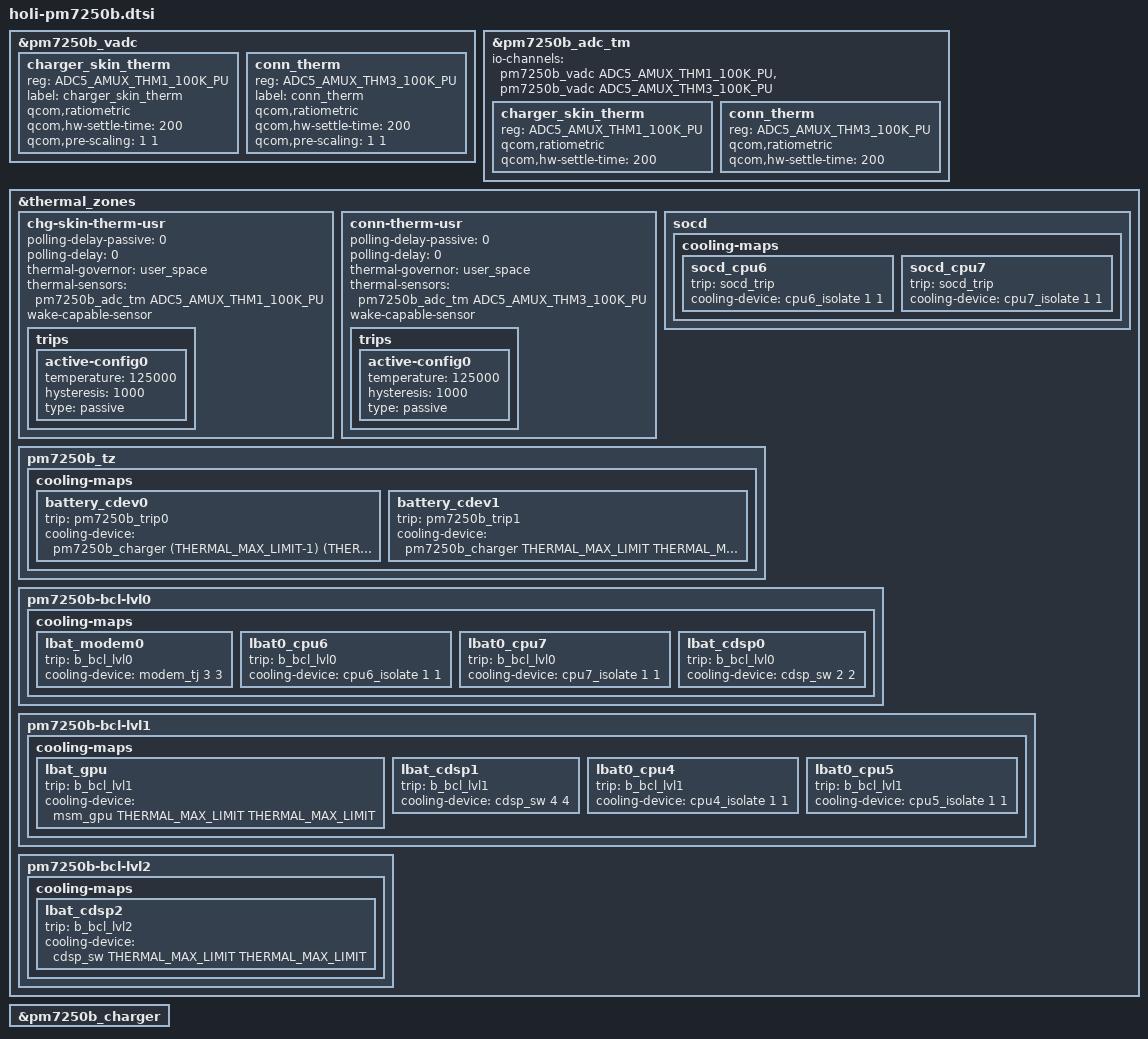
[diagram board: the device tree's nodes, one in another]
#include <dt-bindings/thermal/thermal_qti.h>
#include "pm7250b.dtsi"

&pm7250b_vadc {
	charger_skin_therm {
		reg = <ADC5_AMUX_THM1_100K_PU>;
		label = "charger_skin_therm";
		qcom,ratiometric;
		qcom,hw-settle-time = <200>;
		qcom,pre-scaling = <1 1>;
	};

	conn_therm {
		reg = <ADC5_AMUX_THM3_100K_PU>;
		label = "conn_therm";
		qcom,ratiometric;
		qcom,hw-settle-time = <200>;
		qcom,pre-scaling = <1 1>;
	};
};

&pm7250b_adc_tm {
	io-channels = <&pm7250b_vadc ADC5_AMUX_THM1_100K_PU>,
			<&pm7250b_vadc ADC5_AMUX_THM3_100K_PU>;

	/* Channel nodes */
	charger_skin_therm {
		reg = <ADC5_AMUX_THM1_100K_PU>;
		qcom,ratiometric;
		qcom,hw-settle-time = <200>;
	};

	conn_therm {
		reg = <ADC5_AMUX_THM3_100K_PU>;
		qcom,ratiometric;
		qcom,hw-settle-time = <200>;
	};
};

&thermal_zones {
	chg-skin-therm-usr {
		polling-delay-passive = <0>;
		polling-delay = <0>;
		thermal-governor = "user_space";
		thermal-sensors = <&pm7250b_adc_tm ADC5_AMUX_THM1_100K_PU>;
		wake-capable-sensor;
		trips {
			active-config0 {
				temperature = <125000>;
				hysteresis = <1000>;
				type = "passive";
			};
		};
	};

	conn-therm-usr {
		polling-delay-passive = <0>;
		polling-delay = <0>;
		thermal-governor = "user_space";
		thermal-sensors = <&pm7250b_adc_tm ADC5_AMUX_THM3_100K_PU>;
		wake-capable-sensor;
		trips {
			active-config0 {
				temperature = <125000>;
				hysteresis = <1000>;
				type = "passive";
			};
		};
	};
};

&pm7250b_charger {
	#cooling-cells = <2>;
};

&thermal_zones {
	socd {
		cooling-maps {
			socd_cpu6 {
				trip = <&socd_trip>;
				cooling-device = <&cpu6_isolate 1 1>;
			};

			socd_cpu7 {
				trip = <&socd_trip>;
				cooling-device = <&cpu7_isolate 1 1>;
			};
		};
	};

	pm7250b_tz {
		cooling-maps {
			battery_cdev0 {
				trip = <&pm7250b_trip0>;
				cooling-device =
					<&pm7250b_charger (THERMAL_MAX_LIMIT-1)
							(THERMAL_MAX_LIMIT-1)>;
			};

			battery_cdev1 {
				trip = <&pm7250b_trip1>;
				cooling-device =
					<&pm7250b_charger THERMAL_MAX_LIMIT
							THERMAL_MAX_LIMIT>;
			};
		};
	};

	pm7250b-bcl-lvl0 {
		cooling-maps {
			lbat_modem0 {
				trip = <&b_bcl_lvl0>;
				cooling-device = <&modem_tj 3 3>;
			};

			lbat0_cpu6 {
				trip = <&b_bcl_lvl0>;
				cooling-device = <&cpu6_isolate 1 1>;
			};

			lbat0_cpu7 {
				trip = <&b_bcl_lvl0>;
				cooling-device = <&cpu7_isolate 1 1>;
			};

			lbat_cdsp0 {
				trip = <&b_bcl_lvl0>;
				cooling-device = <&cdsp_sw 2 2>;
			};
		};
	};

	pm7250b-bcl-lvl1 {
		cooling-maps {
			lbat_gpu {
				trip = <&b_bcl_lvl1>;
				cooling-device = <&msm_gpu THERMAL_MAX_LIMIT
							THERMAL_MAX_LIMIT>;
			};

			lbat_cdsp1 {
				trip = <&b_bcl_lvl1>;
				cooling-device = <&cdsp_sw 4 4>;
			};

			lbat0_cpu4 {
				trip = <&b_bcl_lvl1>;
				cooling-device = <&cpu4_isolate 1 1>;
			};

			lbat0_cpu5 {
				trip = <&b_bcl_lvl1>;
				cooling-device = <&cpu5_isolate 1 1>;
			};
		};
	};

	pm7250b-bcl-lvl2 {
		cooling-maps {
			lbat_cdsp2 {
				trip = <&b_bcl_lvl2>;
				cooling-device = <&cdsp_sw THERMAL_MAX_LIMIT
							THERMAL_MAX_LIMIT>;
			};
		};
	};
};
